VERSION ""

NS_ :

BS_:

BU_: BMS Third_Party_Device

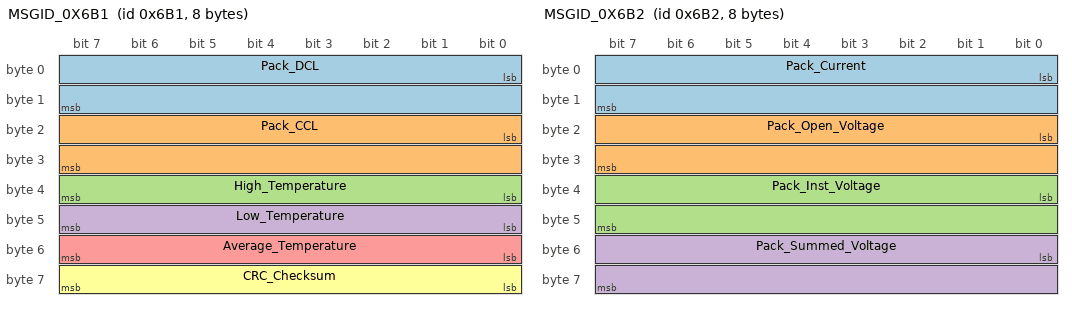
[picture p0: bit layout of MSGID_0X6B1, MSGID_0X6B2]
BO_ 1713 MSGID_0X6B1: 8 BMS
 SG_ Pack_DCL : 0|16@1+ (1.0,0) [0|0] "Amps"  Third_Party_Device
 SG_ Pack_CCL : 16|16@1+ (1.0,0) [0|0] "Amps"  Third_Party_Device
 SG_ High_Temperature : 39|8@0+ (1.0,0) [0|0] "Celsius"  Third_Party_Device
 SG_ Low_Temperature : 47|8@0+ (1.0,0) [0|0] "Celsius"  Third_Party_Device
 SG_ Average_Temperature : 55|8@0+ (1.0,0) [0|0] "Celsius"  Third_Party_Device
 SG_ CRC_Checksum : 63|8@0+ (1.0,1721) [0|0] ""  Third_Party_Device

BO_ 1714 MSGID_0X6B2: 8 BMS
 SG_ Pack_Current : 0|16@1- (0.1,0) [0|0] "Amps"  Third_Party_Device
 SG_ Pack_Open_Voltage : 16|16@1+ (0.1,0) [0|0] "Volts"  Third_Party_Device
 SG_ Pack_Inst_Voltage : 32|16@1+ (0.1,0) [0|0] "Volts"  Third_Party_Device
 SG_ Pack_Summed_Voltage : 48|16@1+ (0.01,0) [0|0] "Volts"  Third_Party_Device

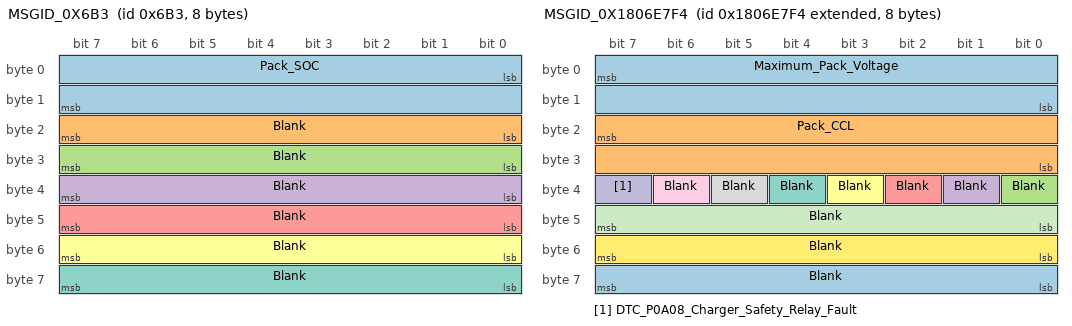
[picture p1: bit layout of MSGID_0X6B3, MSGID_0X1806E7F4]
BO_ 1715 MSGID_0X6B3: 8 BMS
 SG_ Pack_SOC : 0|16@1+ (0.5,0) [0|0] "Percent"  Third_Party_Device
 SG_ Blank : 23|8@0+ (1.0,0) [0|0] ""  Third_Party_Device
 SG_ Blank : 31|8@0+ (1.0,0) [0|0] ""  Third_Party_Device
 SG_ Blank : 39|8@0+ (1.0,0) [0|0] ""  Third_Party_Device
 SG_ Blank : 47|8@0+ (1.0,0) [0|0] ""  Third_Party_Device
 SG_ Blank : 55|8@0+ (1.0,0) [0|0] ""  Third_Party_Device
 SG_ Blank : 63|8@0+ (1.0,0) [0|0] ""  Third_Party_Device

BO_ 2550589428 MSGID_0X1806E7F4: 8 BMS
 SG_ Maximum_Pack_Voltage : 7|16@0+ (0.1,0) [0|0] "Volts"  Third_Party_Device
 SG_ Pack_CCL : 23|16@0+ (0.1,0) [0|0] "Amps"  Third_Party_Device
 SG_ Blank : 32|1@1+ (1.0,0) [0|1] ""  Third_Party_Device
 SG_ Blank : 33|1@1+ (1.0,0) [0|1] ""  Third_Party_Device
 SG_ Blank : 34|1@1+ (1.0,0) [0|1] ""  Third_Party_Device
 SG_ Blank : 35|1@1+ (1.0,0) [0|1] ""  Third_Party_Device
 SG_ Blank : 36|1@1+ (1.0,0) [0|1] ""  Third_Party_Device
 SG_ Blank : 37|1@1+ (1.0,0) [0|1] ""  Third_Party_Device
 SG_ Blank : 38|1@1+ (1.0,0) [0|1] ""  Third_Party_Device
 SG_ DTC_P0A08_Charger_Safety_Relay_Fault : 39|1@1+ (1.0,0) [0|1] ""  Third_Party_Device
 SG_ Blank : 47|8@0+ (0.1,0) [0|0] ""  Third_Party_Device
 SG_ Blank : 55|8@0+ (1.0,0) [0|0] ""  Third_Party_Device
 SG_ Blank : 63|8@0+ (1.0,0) [0|0] ""  Third_Party_Device

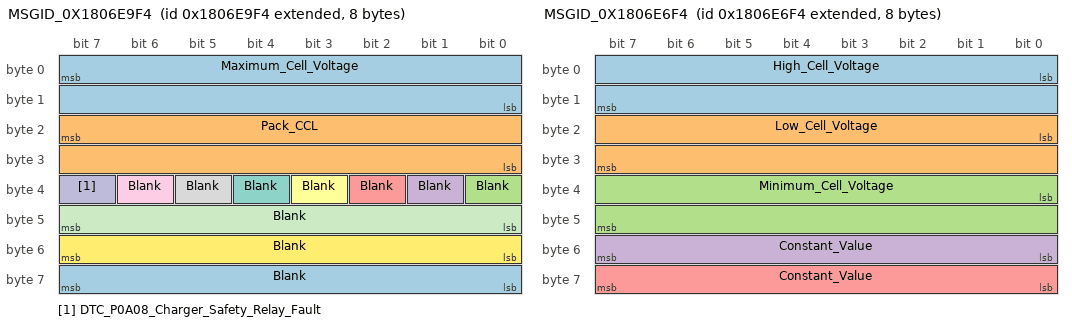
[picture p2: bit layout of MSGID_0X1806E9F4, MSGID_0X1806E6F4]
BO_ 2550589940 MSGID_0X1806E9F4: 8 BMS
 SG_ Maximum_Cell_Voltage : 7|16@0+ (0.001388888888888889,0) [0|0] "Volts"  Third_Party_Device
 SG_ Pack_CCL : 23|16@0+ (0.1,0) [0|0] "Amps"  Third_Party_Device
 SG_ Blank : 32|1@1+ (1.0,0) [0|1] ""  Third_Party_Device
 SG_ Blank : 33|1@1+ (1.0,0) [0|1] ""  Third_Party_Device
 SG_ Blank : 34|1@1+ (1.0,0) [0|1] ""  Third_Party_Device
 SG_ Blank : 35|1@1+ (1.0,0) [0|1] ""  Third_Party_Device
 SG_ Blank : 36|1@1+ (1.0,0) [0|1] ""  Third_Party_Device
 SG_ Blank : 37|1@1+ (1.0,0) [0|1] ""  Third_Party_Device
 SG_ Blank : 38|1@1+ (1.0,0) [0|1] ""  Third_Party_Device
 SG_ DTC_P0A08_Charger_Safety_Relay_Fault : 39|1@1+ (1.0,0) [0|1] ""  Third_Party_Device
 SG_ Blank : 47|8@0+ (1.0,0) [0|0] ""  Third_Party_Device
 SG_ Blank : 55|8@0+ (1.0,0) [0|0] ""  Third_Party_Device
 SG_ Blank : 63|8@0+ (1.0,0) [0|0] ""  Third_Party_Device

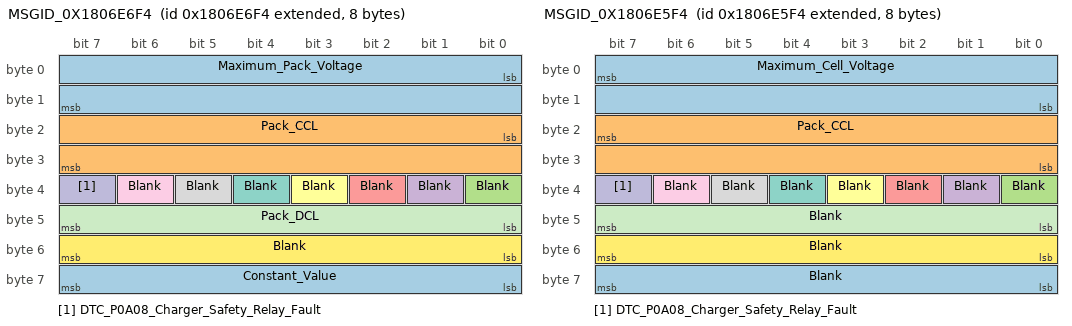
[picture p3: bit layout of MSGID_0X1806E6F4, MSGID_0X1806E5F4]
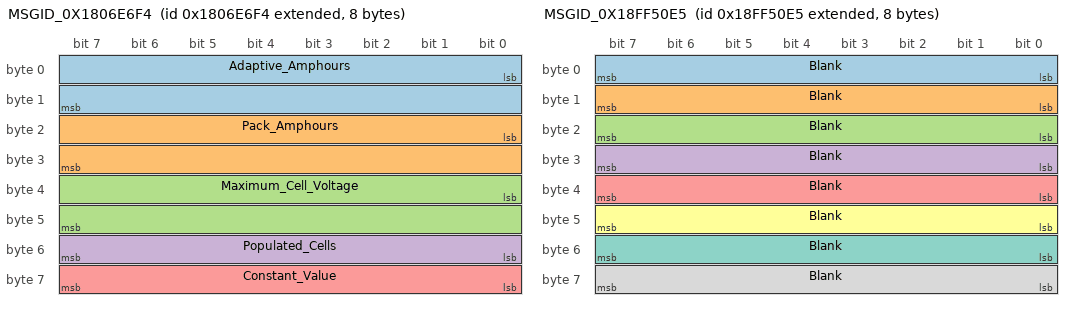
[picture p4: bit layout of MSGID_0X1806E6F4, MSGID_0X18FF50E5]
BO_ 2550589172 MSGID_0X1806E6F4: 8 BMS
 SG_ High_Cell_Voltage : 0|16@1+ (1.0E-4,0) [0|0] "Volts"  Third_Party_Device
 SG_ Low_Cell_Voltage : 16|16@1+ (1.0E-4,0) [0|0] "Volts"  Third_Party_Device
 SG_ Minimum_Cell_Voltage : 32|16@1+ (1.0E-4,0) [0|0] "Volts"  Third_Party_Device
 SG_ Constant_Value : 55|8@0+ (1.0,0) [0|0] ""  Third_Party_Device
 SG_ Constant_Value : 63|8@0+ (1.0,3) [3|3] ""  Third_Party_Device

BO_ 2550589172 MSGID_0X1806E6F4: 8 BMS
 SG_ Maximum_Pack_Voltage : 0|16@1+ (0.1,0) [0|0] "Volts"  Third_Party_Device
 SG_ Pack_CCL : 16|16@1+ (0.1,0) [0|0] "Amps"  Third_Party_Device
 SG_ Blank : 32|1@1+ (1.0,0) [0|1] ""  Third_Party_Device
 SG_ Blank : 33|1@1+ (1.0,0) [0|1] ""  Third_Party_Device
 SG_ Blank : 34|1@1+ (1.0,0) [0|1] ""  Third_Party_Device
 SG_ Blank : 35|1@1+ (1.0,0) [0|1] ""  Third_Party_Device
 SG_ Blank : 36|1@1+ (1.0,0) [0|1] ""  Third_Party_Device
 SG_ Blank : 37|1@1+ (1.0,0) [0|1] ""  Third_Party_Device
 SG_ Blank : 38|1@1+ (1.0,0) [0|1] ""  Third_Party_Device
 SG_ DTC_P0A08_Charger_Safety_Relay_Fault : 39|1@1+ (1.0,0) [0|1] ""  Third_Party_Device
 SG_ Pack_DCL : 47|8@0+ (0.1,0) [0|0] "Amps"  Third_Party_Device
 SG_ Blank : 55|8@0+ (1.0,0) [0|0] ""  Third_Party_Device
 SG_ Constant_Value : 63|8@0+ (1.0,1) [1|1] ""  Third_Party_Device

BO_ 2550588916 MSGID_0X1806E5F4: 8 BMS
 SG_ Maximum_Cell_Voltage : 7|16@0+ (0.001388888888888889,0) [0|0] "Volts"  Third_Party_Device
 SG_ Pack_CCL : 23|16@0+ (0.1,0) [0|0] "Amps"  Third_Party_Device
 SG_ Blank : 32|1@1+ (1.0,0) [0|1] ""  Third_Party_Device
 SG_ Blank : 33|1@1+ (1.0,0) [0|1] ""  Third_Party_Device
 SG_ Blank : 34|1@1+ (1.0,0) [0|1] ""  Third_Party_Device
 SG_ Blank : 35|1@1+ (1.0,0) [0|1] ""  Third_Party_Device
 SG_ Blank : 36|1@1+ (1.0,0) [0|1] ""  Third_Party_Device
 SG_ Blank : 37|1@1+ (1.0,0) [0|1] ""  Third_Party_Device
 SG_ Blank : 38|1@1+ (1.0,0) [0|1] ""  Third_Party_Device
 SG_ DTC_P0A08_Charger_Safety_Relay_Fault : 39|1@1+ (1.0,0) [0|1] ""  Third_Party_Device
 SG_ Blank : 47|8@0+ (0.1,0) [0|0] ""  Third_Party_Device
 SG_ Blank : 55|8@0+ (1.0,0) [0|0] ""  Third_Party_Device
 SG_ Blank : 63|8@0+ (1.0,0) [0|0] ""  Third_Party_Device

BO_ 2550589172 MSGID_0X1806E6F4: 8 BMS
 SG_ Adaptive_Amphours : 0|16@1+ (1.666666666666667,0) [0|0] "Amphours"  Third_Party_Device
 SG_ Pack_Amphours : 16|16@1+ (0.010000000000000002,0) [0|0] "Amphours"  Third_Party_Device
 SG_ Maximum_Cell_Voltage : 32|16@1+ (1.0E-4,6) [0|0] "Volts"  Third_Party_Device
 SG_ Populated_Cells : 55|8@0+ (1.0,0) [0|0] "Num"  Third_Party_Device
 SG_ Constant_Value : 63|8@0+ (1.0,2) [2|2] ""  Third_Party_Device

BO_ 2566869221 MSGID_0X18FF50E5: 8 Third_Party_Device
 SG_ Blank : 7|8@0+ (1.0,0) [0|0] ""  BMS
 SG_ Blank : 15|8@0+ (1.0,0) [0|0] ""  BMS
 SG_ Blank : 23|8@0+ (1.0,0) [0|0] ""  BMS
 SG_ Blank : 31|8@0+ (1.0,0) [0|0] ""  BMS
 SG_ Blank : 39|8@0+ (1.0,0) [0|0] ""  BMS
 SG_ Blank : 47|8@0+ (1.0,0) [0|0] ""  BMS
 SG_ Blank : 55|8@0+ (1.0,0) [0|0] ""  BMS
 SG_ Blank : 63|8@0+ (1.0,0) [0|0] ""  BMS

CM_ BO_ 1713 "This ID Transmits at 104 ms.";
CM_ BO_ 1714 "This ID Transmits at 48 ms.";
CM_ BO_ 1715 "This ID Transmits at 1008 ms.";
CM_ BO_ 2550589428 "This ID Transmits at 808 ms.";
CM_ BO_ 2550589940 "This ID Transmits at 808 ms.";
CM_ BO_ 2550589172 "This ID Transmits at 1000 ms.";
CM_ BO_ 2550589172 "This ID Transmits at 1000 ms.";
CM_ BO_ 2550588916 "This ID Transmits at 808 ms.";
CM_ BO_ 2550589172 "This ID Transmits at 1000 ms.";
